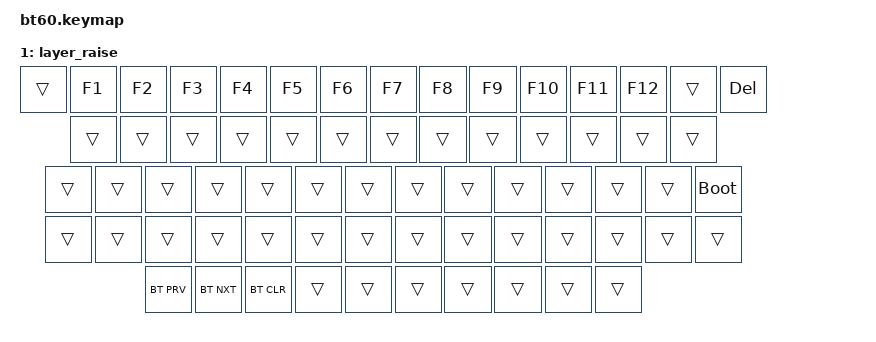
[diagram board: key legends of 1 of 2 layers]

/*
 * Copyright (c) 2020 The ZMK Contributors
 *
 * SPDX-License-Identifier: MIT
 */


/* THIS FILE WAS GENERATED!
 *
 * This file was generated automatically. You may or may not want to
 * edit it directly.
 */

#include <behaviors.dtsi>
#include <dt-bindings/zmk/keys.h>

#include <dt-bindings/zmk/bt.h>

/ {
    keymap {
        compatible = "zmk,keymap";


        default_layer {
            bindings = <
   &kp ESC     &kp N1    &kp N2    &kp N3     &kp N4    &kp N5            &kp N6       &kp N7     &kp N8      &kp N9    &kp N0  &kp MINUS  &kp EQUAL  &kp GRAVE  &kp BSPC
   &kp TAB      &kp Q     &kp W     &kp E      &kp R     &kp T             &kp Y        &kp U      &kp I       &kp O     &kp P   &kp LEFT_BRACKET   &kp RIGHT_BRACKET
  &kp CLCK      &kp A     &kp S     &kp D      &kp F     &kp G             &kp H        &kp J      &kp K       &kp L  &kp SEMI    &kp SQT  &kp NON_US_HASH  &kp RET
 &kp LSHFT   &kp NON_US_BSLH   &kp Z     &kp X     &kp C      &kp V     &kp B             &kp N        &kp M  &kp COMMA     &kp DOT  &kp FSLH  &kp RSHFT &mo 1
            &kp LCTRL  &kp LGUI  &kp LALT  &kp SPACE  &kp RALT             &kp LEFT  &kp DOWN  &kp UP  &kp RIGHT
            >;
        };

        layer_raise {
            bindings = <
  &trans        &kp F1        &kp F2      &kp F3  &kp F4       &kp F5            &kp F6  &kp F7      &kp F8   &kp F9    &kp F10     &kp F11          &kp F12  &trans &kp DEL
     &trans        &trans        &trans      &trans  &trans       &trans            &trans  &trans     &trans   &trans  &trans    &trans  &trans   
     &trans      &trans      &trans   &trans  &trans       &trans            &trans  &trans      &trans   &trans   &trans   &trans   &trans   &bootloader
 &trans  &trans  &trans  &trans  &trans  &trans            &trans  &trans      &trans  &trans  &trans  &trans &trans  &trans
               &bt BT_PRV    &bt BT_NXT      &bt BT_CLR  &trans       &trans            &trans  &trans  &trans   &trans  &trans
            >;
        };

    };
};
